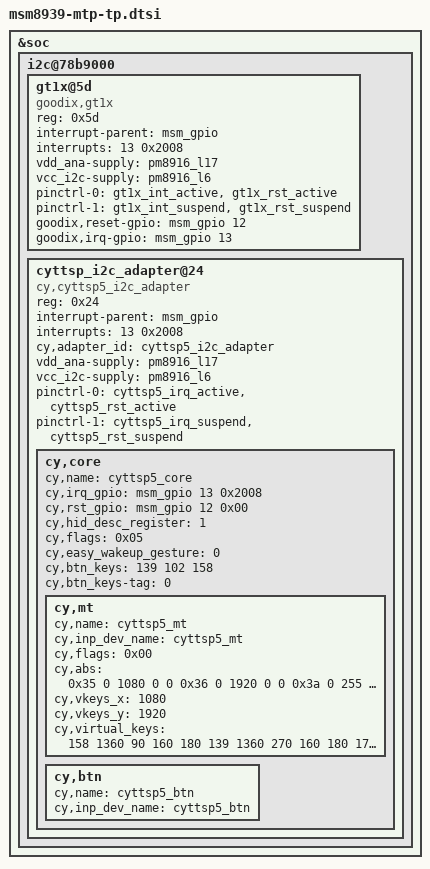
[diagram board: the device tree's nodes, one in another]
/* Copyright (c) 2014, The Linux Foundation. All rights reserved.
 *
 * This program is free software; you can redistribute it and/or modify
 * it under the terms of the GNU General Public License version 2 and
 * only version 2 as published by the Free Software Foundation.
 *
 * This program is distributed in the hope that it will be useful,
 * but WITHOUT ANY WARRANTY; without even the implied warranty of
 * MERCHANTABILITY or FITNESS FOR A PARTICULAR PURPOSE.  See the
 * GNU General Public License for more details.
 */

&soc {
	i2c@78b9000 { /* BLSP1 QUP5 */
		gt1x@5d {
			compatible = "goodix,gt1x";
			reg = <0x5d>;
			interrupt-parent = <&msm_gpio>;
			interrupts = <13 0x2008>;
			vdd_ana-supply = <&pm8916_l17>;
			vcc_i2c-supply = <&pm8916_l6>;
			pinctrl-names = "gt1x_pin_active","gt1x_pin_suspend";
			pinctrl-0 = <&gt1x_int_active &gt1x_rst_active>;
			pinctrl-1 = <&gt1x_int_suspend &gt1x_rst_suspend>;
			goodix,reset-gpio = <&msm_gpio 12 0x00>;
			goodix,irq-gpio = <&msm_gpio 13 0x2008>;
		};
		cyttsp_i2c_adapter@24 {
			compatible = "cy,cyttsp5_i2c_adapter";
			reg = <0x24>;
			interrupt-parent = <&msm_gpio>;
			interrupts = <13 0x2008>;
			cy,adapter_id = "cyttsp5_i2c_adapter";
			vdd_ana-supply = <&pm8916_l17>;
			vcc_i2c-supply = <&pm8916_l6>;
			pinctrl-names = "cyttsp5_pin_active", "cyttsp5_pin_suspend";
			pinctrl-0 = <&cyttsp5_irq_active &cyttsp5_rst_active>;
			pinctrl-1 = <&cyttsp5_irq_suspend &cyttsp5_rst_suspend>;
			cy,core {
				cy,name = "cyttsp5_core";
				cy,irq_gpio = <&msm_gpio 13 0x2008>;
				cy,rst_gpio = <&msm_gpio 12 0x00>;
				cy,hid_desc_register = <1>;
				/* CY_CORE_FLAG_WAKE_ON_GESTURE | CY_CORE_FLAG_RESTORE_PARAMETERS */
				cy,flags = <0x05>;
				/* CY_CORE_EWG_NONE */
				cy,easy_wakeup_gesture = <0>;
				cy,btn_keys = <139	/* KEY_MENU */
				          102 /* KEY_HOMEPAGE */
					       158>;	/* KEY_BACK */
				cy,btn_keys-tag = <0>;

				cy,mt {
					cy,name = "cyttsp5_mt";

					cy,inp_dev_name = "cyttsp5_mt";
					cy,flags = <0x00>;
					cy,abs =
						/* ABS_MT_POSITION_X, CY_ABS_MIN_X, CY_ABS_MAX_X, 0, 0 */
						<0x35 0 1080 0 0
						/* ABS_MT_POSITION_Y, CY_ABS_MIN_Y, CY_ABS_MAX_Y, 0, 0 */
						0x36 0 1920 0 0
						/* ABS_MT_PRESSURE, CY_ABS_MIN_P, CY_ABS_MAX_P, 0, 0 */
						0x3a 0 255 0 0
						/* CY_IGNORE_VALUE, CY_ABS_MIN_W, CY_ABS_MAX_W, 0, 0 */
						0xffff 0 255 0 0
						/* ABS_MT_TRACKING_ID, CY_ABS_MIN_T, CY_ABS_MAX_T, 0, 0 */
						0x39 0 15 0 0
						/* ABS_MT_TOUCH_MAJOR, 0, 255, 0, 0 */
						0x30 0 255 0 0
						/* ABS_MT_TOUCH_MINOR, 0, 255, 0, 0 */
						0x31 0 255 0 0
						/* ABS_MT_ORIENTATION, -127, 127, 0, 0 */
						0x34 0xffffff81 127 0 0
						/* ABS_MT_TOOL_TYPE, 0, MT_TOOL_MAX, 0, 0 */
						/* 0x37 0 1 0 0 */
						/* ABS_DISTANCE, 0, 255, 0, 0 */
						0x19 0 255 0 0>;

					cy,vkeys_x = <1080>;
					cy,vkeys_y = <1920>;

					cy,virtual_keys = /* KeyCode CenterX CenterY Width Height */
						/* KEY_BACK */
						<158 1360 90 160 180
						/* KEY_MENU */
						139 1360 270 160 180
						/* KEY_HOMEPAGE */
						172 1360 450 160 180
						/* KEY SEARCH */
						217 1360 630 160 180>;
				};

				cy,btn {
					cy,name = "cyttsp5_btn";

					cy,inp_dev_name = "cyttsp5_btn";
				};
			};
		};
	};
};

